# ATSAM4E16E register map
Vendor: Atmel; Series: SAM4E; File version: 0
CPU: CM4 r0p0, selectable endian, MPU, FPU, 4 interrupt priority bits
Registers are 32-bit, read-write, reset 0x0 unless marked. A register's access mark holds for its fields unless they carry their own. Offsets are from the block's base; [hi:lo] are bit positions; {n}, {i} and the like mark numbered series.

## PIOA — Parallel Input/Output Controller A
Base 0x400E0E00; register names take the prefix PIOA_
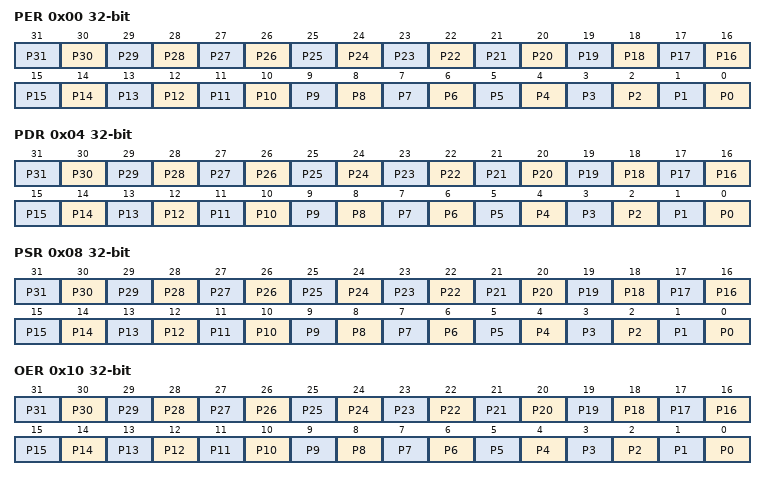
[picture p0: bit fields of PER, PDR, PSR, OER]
0x00 PER wo reset not defined — PIO Enable Register
  [n] P{n} (n=0..31) — PIO Enable
0x04 PDR wo reset not defined — PIO Disable Register
  [n] P{n} (n=0..31) — PIO Disable
0x08 PSR ro reset not defined — PIO Status Register
  [n] P{n} (n=0..31) — PIO Status
0x10 OER wo reset not defined — Output Enable Register
  [n] P{n} (n=0..31) — Output Enable
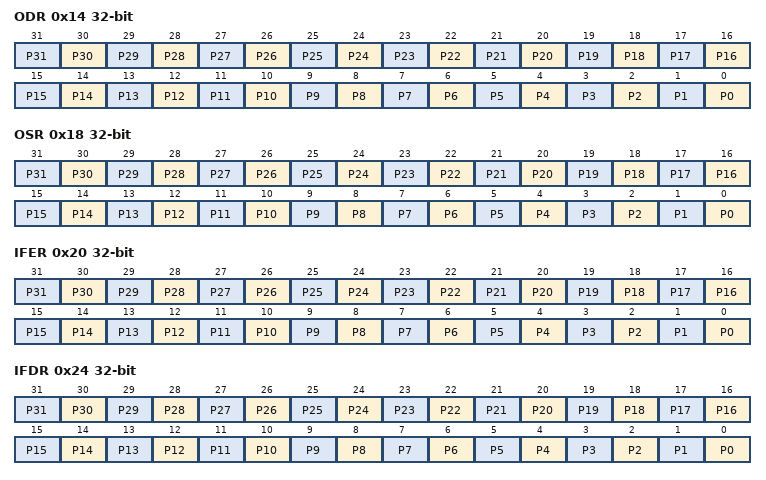
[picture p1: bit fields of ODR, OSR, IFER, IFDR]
0x14 ODR wo reset not defined — Output Disable Register
  [n] P{n} (n=0..31) — Output Disable
0x18 OSR ro — Output Status Register
  [n] P{n} (n=0..31) — Output Status
0x20 IFER wo reset not defined — Glitch Input Filter Enable Register
  [n] P{n} (n=0..31) — Input Filter Enable
0x24 IFDR wo reset not defined — Glitch Input Filter Disable Register
  [n] P{n} (n=0..31) — Input Filter Disable
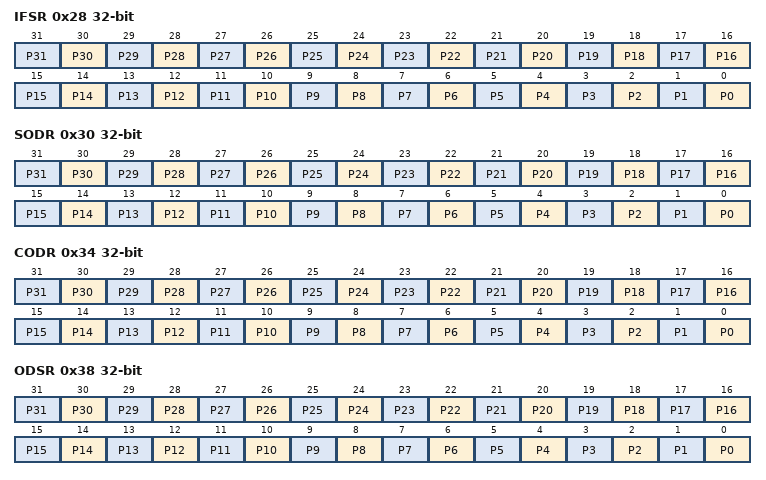
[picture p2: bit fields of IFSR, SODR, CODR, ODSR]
0x28 IFSR ro — Glitch Input Filter Status Register
  [n] P{n} (n=0..31) — Input Filer Status
0x30 SODR wo reset not defined — Set Output Data Register
  [n] P{n} (n=0..31) — Set Output Data
0x34 CODR wo reset not defined — Clear Output Data Register
  [n] P{n} (n=0..31) — Clear Output Data
0x38 ODSR reset not defined — Output Data Status Register
  [n] P{n} (n=0..31) — Output Data Status
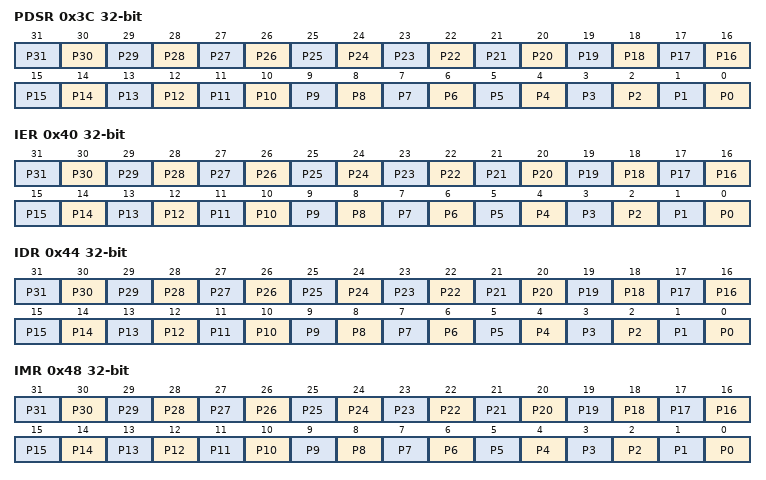
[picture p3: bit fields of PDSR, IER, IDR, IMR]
0x3C PDSR ro reset not defined — Pin Data Status Register
  [n] P{n} (n=0..31) — Output Data Status
0x40 IER wo reset not defined — Interrupt Enable Register
  [n] P{n} (n=0..31) — Input Change Interrupt Enable
0x44 IDR wo reset not defined — Interrupt Disable Register
  [n] P{n} (n=0..31) — Input Change Interrupt Disable
0x48 IMR ro — Interrupt Mask Register
  [n] P{n} (n=0..31) — Input Change Interrupt Mask
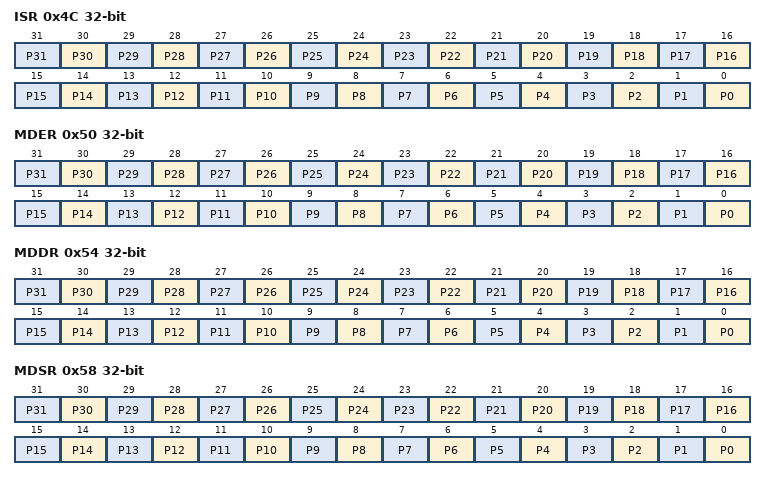
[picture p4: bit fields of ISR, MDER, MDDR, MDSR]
0x4C ISR ro — Interrupt Status Register
  [n] P{n} (n=0..31) — Input Change Interrupt Status
0x50 MDER wo reset not defined — Multi-driver Enable Register
  [n] P{n} (n=0..31) — Multi Drive Enable
0x54 MDDR wo reset not defined — Multi-driver Disable Register
  [n] P{n} (n=0..31) — Multi Drive Disable
0x58 MDSR ro — Multi-driver Status Register
  [n] P{n} (n=0..31) — Multi Drive Status
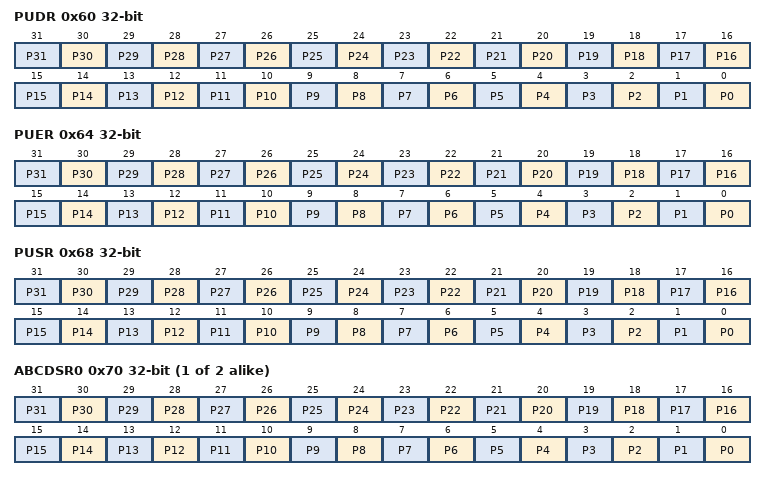
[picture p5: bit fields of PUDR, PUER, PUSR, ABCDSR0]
0x60 PUDR wo reset not defined — Pull-up Disable Register
  [n] P{n} (n=0..31) — Pull Up Disable
0x64 PUER wo reset not defined — Pull-up Enable Register
  [n] P{n} (n=0..31) — Pull Up Enable
0x68 PUSR ro reset not defined — Pad Pull-up Status Register
  [n] P{n} (n=0..31) — Pull Up Status
{0x70+4i} ABCDSR{i} (i=0..1) reset not defined — Peripheral Select Register
  [n] P{n} (n=0..31) — Peripheral Select
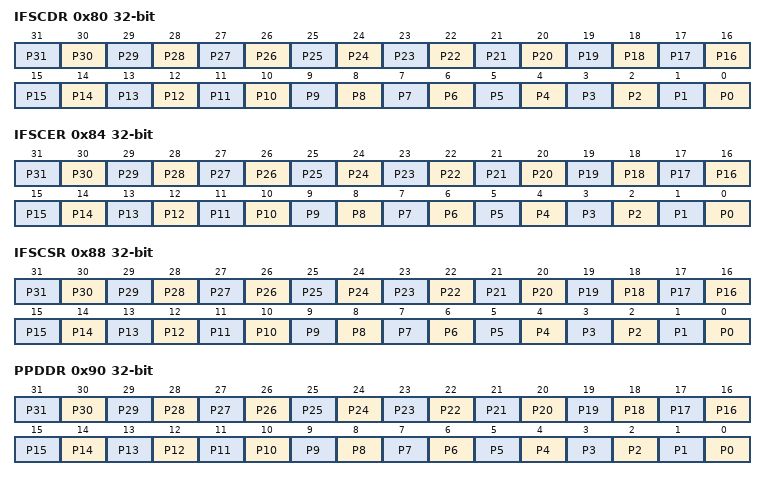
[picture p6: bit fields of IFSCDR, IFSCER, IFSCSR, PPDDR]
0x80 IFSCDR wo reset not defined — Input Filter Slow Clock Disable Register
  [n] P{n} (n=0..31) — PIO Clock Glitch Filtering Select
0x84 IFSCER wo reset not defined — Input Filter Slow Clock Enable Register
  [n] P{n} (n=0..31) — Debouncing Filtering Select
0x88 IFSCSR ro — Input Filter Slow Clock Status Register
  [n] P{n} (n=0..31) — Glitch or Debouncing Filter Selection Status
0x8C SCDR — Slow Clock Divider Debouncing Register
  [13:0] DIV
0x90 PPDDR wo reset not defined — Pad Pull-down Disable Register
  [n] P{n} (n=0..31) — Pull Down Disable
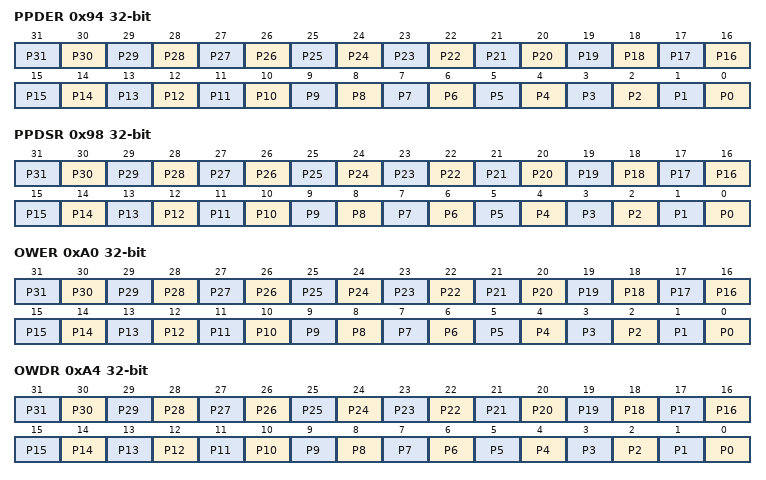
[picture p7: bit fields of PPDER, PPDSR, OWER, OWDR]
0x94 PPDER wo reset not defined — Pad Pull-down Enable Register
  [n] P{n} (n=0..31) — Pull Down Enable
0x98 PPDSR ro reset not defined — Pad Pull-down Status Register
  [n] P{n} (n=0..31) — Pull Down Status
0xA0 OWER wo reset not defined — Output Write Enable
  [n] P{n} (n=0..31) — Output Write Enable
0xA4 OWDR wo reset not defined — Output Write Disable
  [n] P{n} (n=0..31) — Output Write Disable
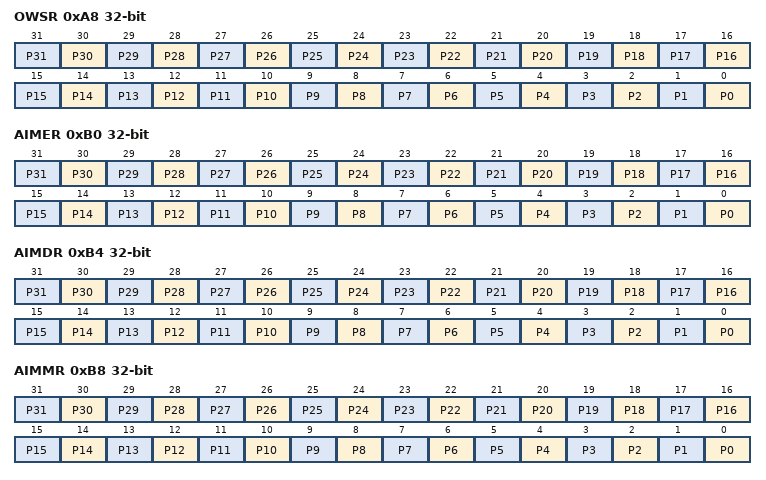
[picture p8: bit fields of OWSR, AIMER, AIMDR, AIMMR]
0xA8 OWSR ro — Output Write Status Register
  [n] P{n} (n=0..31) — Output Write Status
0xB0 AIMER wo reset not defined — Additional Interrupt Modes Enable Register
  [n] P{n} (n=0..31) — Additional Interrupt Modes Enable
0xB4 AIMDR wo reset not defined — Additional Interrupt Modes Disables Register
  [n] P{n} (n=0..31) — Additional Interrupt Modes Disable
0xB8 AIMMR ro — Additional Interrupt Modes Mask Register
  [n] P{n} (n=0..31) — Peripheral CD Status
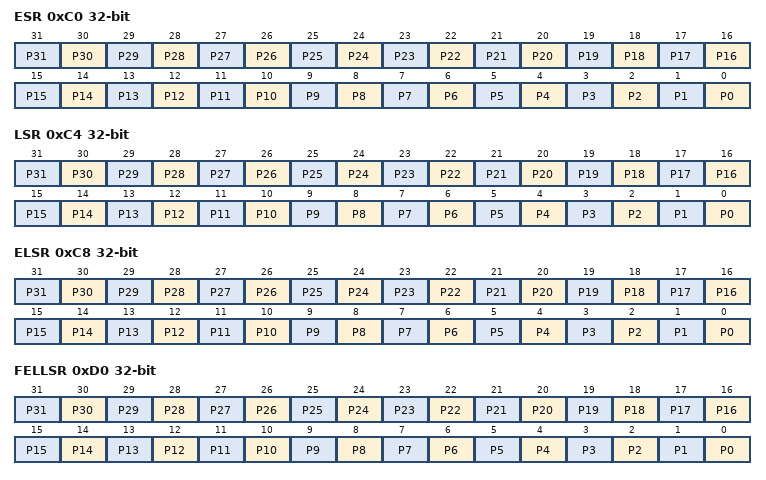
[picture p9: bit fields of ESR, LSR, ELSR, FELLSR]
0xC0 ESR wo reset not defined — Edge Select Register
  [n] P{n} (n=0..31) — Edge Interrupt Selection
0xC4 LSR wo reset not defined — Level Select Register
  [n] P{n} (n=0..31) — Level Interrupt Selection
0xC8 ELSR ro — Edge/Level Status Register
  [n] P{n} (n=0..31) — Edge/Level Interrupt source selection
0xD0 FELLSR wo reset not defined — Falling Edge/Low Level Select Register
  [n] P{n} (n=0..31) — Falling Edge/Low Level Interrupt Selection
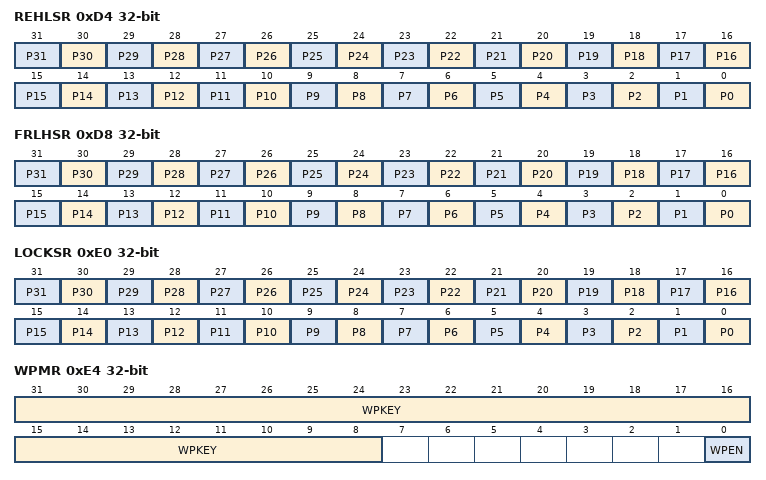
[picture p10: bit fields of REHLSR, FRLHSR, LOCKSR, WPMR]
0xD4 REHLSR wo reset not defined — Rising Edge/ High Level Select Register
  [n] P{n} (n=0..31) — Rising Edge /High Level Interrupt Selection
0xD8 FRLHSR ro — Fall/Rise - Low/High Status Register
  [n] P{n} (n=0..31) — Edge /Level Interrupt Source Selection
0xE0 LOCKSR ro — Lock Status
  [n] P{n} (n=0..31) — Lock Status
0xE4 WPMR — Write Protect Mode Register
  [31:8] WPKEY — Write Protect KEY
  [0] WPEN — Write Protect Enable
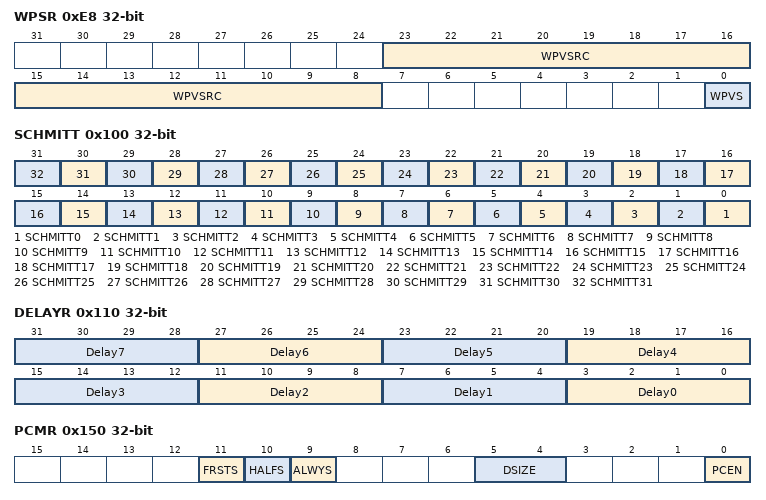
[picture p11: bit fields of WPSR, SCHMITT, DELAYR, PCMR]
0xE8 WPSR ro — Write Protect Status Register
  [23:8] WPVSRC — Write Protect Violation Source
  [0] WPVS — Write Protect Violation Status
0x100 SCHMITT — Schmitt Trigger Register
  [n] SCHMITT{n} (n=0..31)
0x110 DELAYR — IO Delay Register
  [4n+3:4n] Delay{n} (n=0..7)
0x150 PCMR — Parallel Capture Mode Register
  [11] FRSTS — Parallel Capture Mode First Sample
  [10] HALFS — Parallel Capture Mode Half Sampling
  [9] ALWYS — Parallel Capture Mode Always Sampling
  [5:4] DSIZE — Parallel Capture Mode Data Size
    0=BYTE (The reception data in the PIO_PCRHR register is a BYTE (8-bit)); 1=HALFWORD (The reception data in the PIO_PCRHR register is a HALF-WORD (16-bit)); 2=WORD (The reception data in the PIO_PCRHR register is a WORD (32-bit))
  [0] PCEN — Parallel Capture Mode Enable
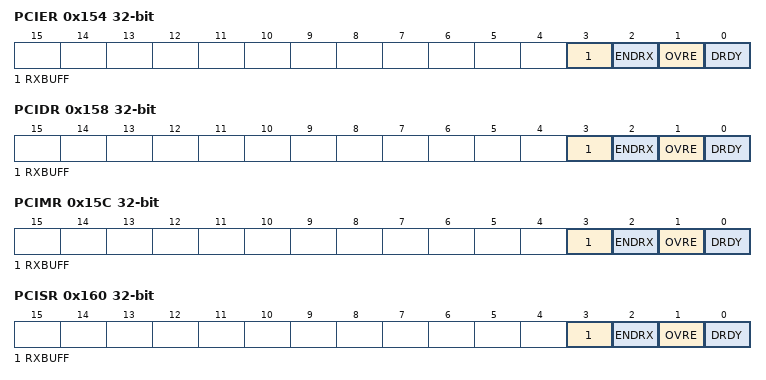
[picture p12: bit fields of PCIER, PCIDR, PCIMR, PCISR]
0x154 PCIER wo reset not defined — Parallel Capture Interrupt Enable Register
  [3] RXBUFF — Reception Buffer Full Interrupt Enable
  [2] ENDRX — End of Reception Transfer Interrupt Enable
  [1] OVRE — Parallel Capture Mode Overrun Error Interrupt Enable
  [0] DRDY — Parallel Capture Mode Data Ready Interrupt Enable
0x158 PCIDR wo reset not defined — Parallel Capture Interrupt Disable Register
  [3] RXBUFF — Reception Buffer Full Interrupt Disable
  [2] ENDRX — End of Reception Transfer Interrupt Disable
  [1] OVRE — Parallel Capture Mode Overrun Error Interrupt Disable
  [0] DRDY — Parallel Capture Mode Data Ready Interrupt Disable
0x15C PCIMR ro — Parallel Capture Interrupt Mask Register
  [3] RXBUFF — Reception Buffer Full Interrupt Mask
  [2] ENDRX — End of Reception Transfer Interrupt Mask
  [1] OVRE — Parallel Capture Mode Overrun Error Interrupt Mask
  [0] DRDY — Parallel Capture Mode Data Ready Interrupt Mask
0x160 PCISR ro — Parallel Capture Interrupt Status Register
  [3] RXBUFF — Reception Buffer Full
  [2] ENDRX — End of Reception Transfer
  [1] OVRE — Parallel Capture Mode Overrun Error
  [0] DRDY — Parallel Capture Mode Data Ready
0x164 PCRHR ro — Parallel Capture Reception Holding Register
  [31:0] RDATA — Parallel Capture Mode Reception Data
0x168 RPR — Receive Pointer Register
  [31:0] RXPTR
0x16C RCR — Receive Counter Register
  [15:0] RXCTR
0x178 RNPR — Receive Next Pointer Register
  [31:0] RXNPTR — Receive Next Pointer
0x17C RNCR — Receive Next Counter Register
  [15:0] RXNCTR — Receive Next Counter
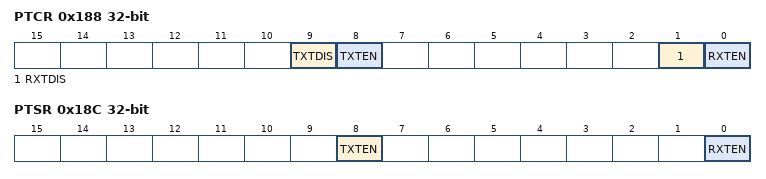
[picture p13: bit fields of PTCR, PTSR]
0x188 PTCR wo — Transfer Control Register
  [9] TXTDIS — Transmitter Transfer Disable
  [8] TXTEN — Transmitter Transfer Enable
  [1] RXTDIS — Receiver Transfer Disable
  [0] RXTEN — Receiver Transfer Enable
0x18C PTSR ro — Transfer Status Register
  [8] TXTEN — Transmitter Transfer Enable
  [0] RXTEN — Receiver Transfer Enable

## PIOB — Parallel Input/Output Controller B
Base 0x400E1000; register names take the prefix PIOB_
Registers as PIOA, without ABCDSR*, RPR, RCR, RNPR, RNCR, PTCR, PTSR; these are added or differ:
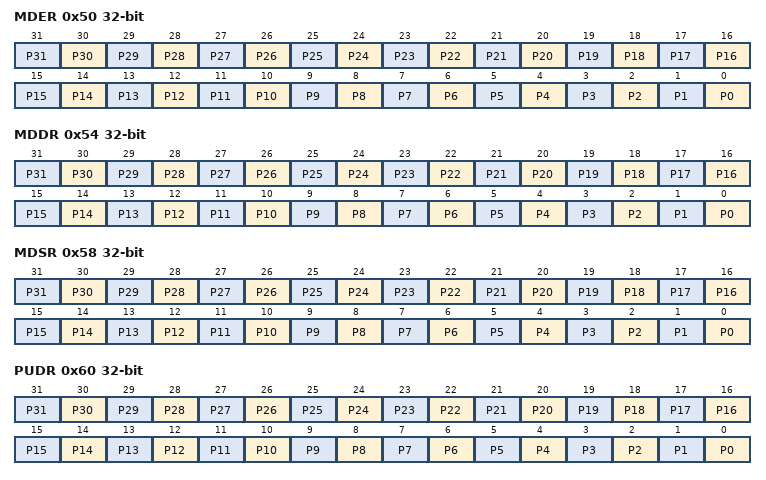
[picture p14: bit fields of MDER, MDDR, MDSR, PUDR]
0x50 MDER wo reset not defined — Multi-driver Enable Register
  [n] P{n} (n=0..31) — Multi-drive Enable
0x54 MDDR wo reset not defined — Multi-driver Disable Register
  [n] P{n} (n=0..31) — Multi-drive Disable
0x58 MDSR ro — Multi-driver Status Register
  [n] P{n} (n=0..31) — Multi-drive Status
0x60 PUDR wo reset not defined — Pull-up Disable Register
  [n] P{n} (n=0..31) — Pull-Up Disable
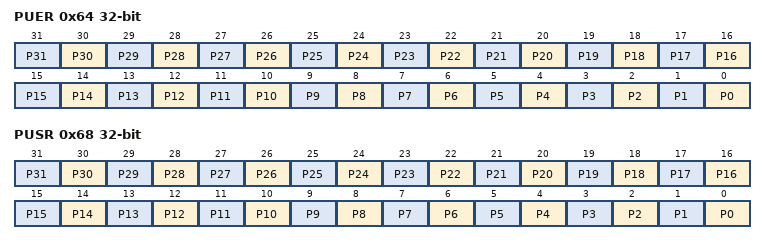
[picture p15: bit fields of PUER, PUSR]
0x64 PUER wo reset not defined — Pull-up Enable Register
  [n] P{n} (n=0..31) — Pull-Up Enable
0x68 PUSR ro reset not defined — Pad Pull-up Status Register
  [n] P{n} (n=0..31) — Pull-Up Status
{0x70+4i} ABCDSR[{i}] (i=0..1) reset not defined — Peripheral Select Register
  [n] P{n} (n=0..31) — Peripheral Select
0x80 IFSCDR wo reset not defined — Input Filter Slow Clock Disable Register
  [n] P{n} (n=0..31) — Peripheral Clock Glitch Filtering Select
0x84 IFSCER wo reset not defined — Input Filter Slow Clock Enable Register
  [n] P{n} (n=0..31) — Slow Clock Debouncing Filtering Select
0x8C SCDR — Slow Clock Divider Debouncing Register
  [13:0] DIV — Slow Clock Divider Selection for Debouncing
0x90 PPDDR wo reset not defined — Pad Pull-down Disable Register
  [n] P{n} (n=0..31) — Pull-Down Disable
0x94 PPDER wo reset not defined — Pad Pull-down Enable Register
  [n] P{n} (n=0..31) — Pull-Down Enable
0x98 PPDSR ro reset not defined — Pad Pull-down Status Register
  [n] P{n} (n=0..31) — Pull-Down Status

## PIOC — Parallel Input/Output Controller C
Base 0x400E1200; register names take the prefix PIOC_
Registers as PIOA, without RPR, RCR, RNPR, RNCR, PTCR, PTSR.

## PIOD — Parallel Input/Output Controller D
Base 0x400E1400; register names take the prefix PIOD_
Registers as PIOA, without RPR, RCR, RNPR, RNCR, PTCR, PTSR.

## PIOE — Parallel Input/Output Controller E
Base 0x400E1600; register names take the prefix PIOE_
Registers as PIOA, without RPR, RCR, RNPR, RNCR, PTCR, PTSR.
